# vpac_targetdb register map
Vendor: Texas Instruments
Peripheral module from a debugger description file (folder hts_vpac).
Registers are 32-bit, read-write, no defined reset value unless marked. A register's access mark holds for its fields unless they carry their own. Offsets are as the file gives them; lines under a group give offsets from that group; [hi:lo] are bit positions; {n}, {i} and the like mark numbered series; 'fields as' and 'values as' point back to an identical list; <NAME> marks a mode.

## VPAC (part 1 of 8) — Vision Pre-Processing Accelerator (VPAC)
0x0C SYSCONFIG — system Configuration
  [1] CLKCG_OVERIDE — Override power saving clock gating inserted by design. '1' -> Allow the clock to be free running (except for gated pixel clock) '0' -> Clock can be gated as planned by the design
0x0C GLBCE_CONTROL1 access per field — Connected to iridix_control1 parameter in GLBCE Core
  [7:0] CONTROL1 rw — Connected Control1 port
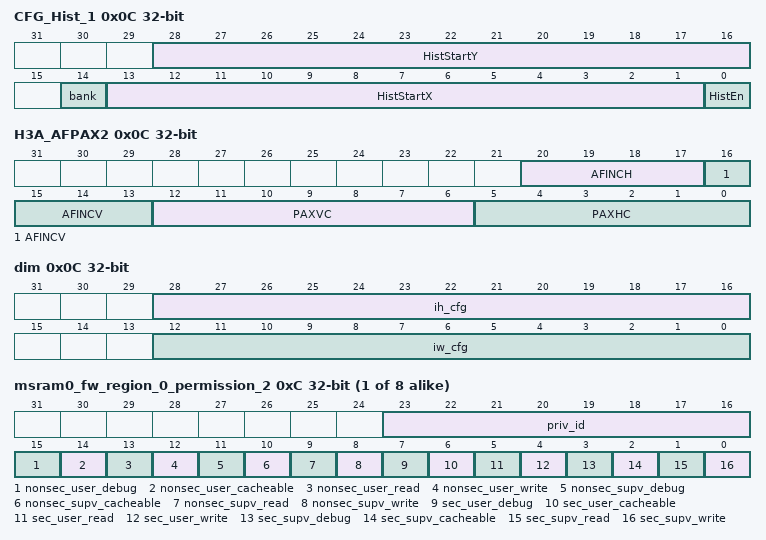
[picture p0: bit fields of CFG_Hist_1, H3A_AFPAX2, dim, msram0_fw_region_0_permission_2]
0x0C CFG_Hist_1 access per field — Configuration-1 Register for histogram
  [28:16] HistStartY rw — Y Start for Histogram ROI, should be >= 1
  [14] bank rw — bank select for Histogram
  [13:1] HistStartX rw — X Start for Histogram ROI, should be even
  [0] HistEn rw — Enable bit for histogram
0x0C PWL1_EN access per field — Long frame PWL enable
  [0] ENABLE rw
0x0C H3A_AFPAX2 access per field — Setup for the AF Engine Paxel Configuration
  [20:17] AFINCH rw — AF Engine Column Increments Number of columns to increment in a paxel plus 1 multiplied by 2 Thus, the number of columns that can be skipped between two processed line pairs is 2-32 [even] The starting two columns in a paxel are first processed before this field is applied This must be set so that there are at least 4 samples on a line when combined with the number of horizontal paxels * This value is shadowed and latched on the rising edge of VSYNC
  [16:13] AFINCV rw — AF Engine Line Increments Number of lines to increment in a Paxel plus 1 multiplied by 2 Incrementing the line in a paxel is always done on a line pair due to the fact that the RGB pattern falls in two lines If all the lines are to be processed, this field should be set to zero, and thus line count is incremented by 2 following a line pair Thus, the number of lines that can be skipped between two processed line pairs is 0-30 [even] The starting two lines in a paxel are first processed before this field is applied * This value is shadowed and latched on the rising edge of VSYNC
  [12:6] PAXVC rw — AF Engine Vertical Paxel Count The number of paxels in the vertical direction plus 1 The maximum number of vertical paxels in a frame should not exceed 128 The value should be set to ensure that the bandwidth requirements and buffer size are not exceeded * This value is shadowed and latched on the rising edge of VSYNC
  [5:0] PAXHC rw — AF Engine Horizontal Paxel Count The number of paxels in the horizontal direction plus 1 It is illegal to set a number that is greater than 35 [total of 36 paxels in the horizontal direction] The minimum number of paxels should be 2 [valid range for the field is 1-35] * This value is shadowed and latched on the rising edge of VSYNC
0x0C dim — Input Output Frame dimensions in units of pixels. Same value for input and output
  [28:16] ih_cfg — (U13) input height in units of pixels minus 1.
  [12:0] iw_cfg — (U13) input width in units of pixels minus 1. Max usable value determined by populated line buffer RAM size
0x0C YEE_SHIFT — The YEE Shift register controls
  [5:0] yee_shift
{0xC+0x20*i} msram0_fw_region_{i}_permission_2 (i=0..7) — The FW Region {i} Permission 2 Register defines the permissions for the slave ksbus_msram0.slv region {i} firewall.
  [23:16] priv_id — Allowed privid.
  [15] nonsec_user_debug — Non-secure user debug allowed.
  [14] nonsec_user_cacheable — Non-secure user cacheable allowed.
  [13] nonsec_user_read — Non-secure user read allowed.
  [12] nonsec_user_write — Non-secure user write allowed.
  [11] nonsec_supv_debug — Non-secure supervisor debug allowed.
  [10] nonsec_supv_cacheable — Non-secure supervisor cacheable allowed.
  [9] nonsec_supv_read — Non-secure supervisor read allowed.
  [8] nonsec_supv_write — Non-secure supervisor write allowed.
  [7] sec_user_debug — Secure user debug allowed.
  [6] sec_user_cacheable — Secure user cacheable allowed.
  [5] sec_user_read — Secure user read allowed.
  [4] sec_user_write — Secure user write allowed.
  [3] sec_supv_debug — Secure supervisor debug allowed.
  [2] sec_supv_cacheable — Secure supervisor cacheable allowed.
  [1] sec_supv_read — Secure supervisor read allowed.
  [0] sec_supv_write — Secure supervisor write allowed.
0x10 eoi_reg — End of Interrupt Register
  [7:0] eoi_vector — End of Interrupt Vector
0x10 reserved_svbus — Reference other documents that contain the ECC RAM wrapper and EDC controller serial vbus register sets.
  [31:0] data — Serial VBUS register data
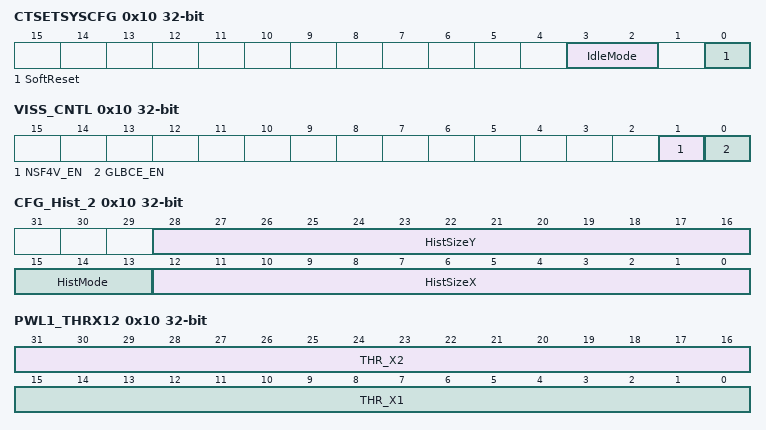
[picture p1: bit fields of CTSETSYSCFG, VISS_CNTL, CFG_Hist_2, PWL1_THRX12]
0x10 CTSETSYSCFG access per field — CTSET system configuration register
  [3:2] IdleMode rw — Sets the Idle Mode for CTSET (0=Force Idle, 1=No Idle, 2=Smart Idle, 3= Smart Idle wakeup)
  [0] SoftReset rw — This will reset entire CTSET, except the registers and the CFG interface. This bit is automatically cleared by hardware. Reads always return 0
0x10 reserved_svbus — Reference other documents that contain the ECC RAM wrapper and EDC controller serial vbus register sets.
  [31:0] data — Serial VBUS register data
0x10 MESHTABLE_CFG — Defines the down-sampling factors used for the mesh offset tables
  [2:0] M — Mesh table down-sampling factor (by 2^M in both horizontal and Vertical). 0: 1 - no down-sampling 1: 2 - 2x down-sampling 2: 4 3: 8 4: 16 5: 32 6: 64 7:128
0x10 reserved_svbus — Reference other documents that contain the ECC RAM wrapper and EDC controller serial vbus register sets.
  [31:0] data — Serial VBUS register data
0x10 VISS_CNTL — VISS top control
  [1] NSF4V_EN — '1' -> NSF4V is ON , '0' -> NSF4V is off i.e. bypass NSF4V. Read the bit status for completion of write. When '0', Configuration access to NSF4V will result in Error response.
  [0] GLBCE_EN — '1' -> GLBCE is ON , '0' -> GLBCE is off i.e. bypass GLBCE. Read the bit status for completion of write. When '0', Configuration access to GLBCE End points (MMR, Statastics memory ) will result in Error response.
0x10 GLBCE_BLACK_LEVEL access per field — Black Level Register (black_level)
  [15:0] VAL rw — The value stored in Black Level Port will be used as zero level for GLBCE processing in all unsigned data channels Data below Black level will not be processed and stay unchanged
0x10 CFG_Hist_2 access per field — Configuration-2 Register for histogram
  [28:16] HistSizeY rw — Y Size (Height) for Histogram ROI
  [15:13] HistMode rw — Histogram Mode(0:Col-0(R),1:Col-1(G),2:Col-2(B),3:MuxC1_4,4:R+2G+B/4 )
  [12:0] HistSizeX rw — X Size (Width) for Histogram ROI, should be > 256 and even
0x10 PWL1_THRX12 — Long frame PWL threshold X1 and X2 - Unsigned
  [31:16] THR_X2 — threshold X2
  [15:0] THR_X1 — threshold X1
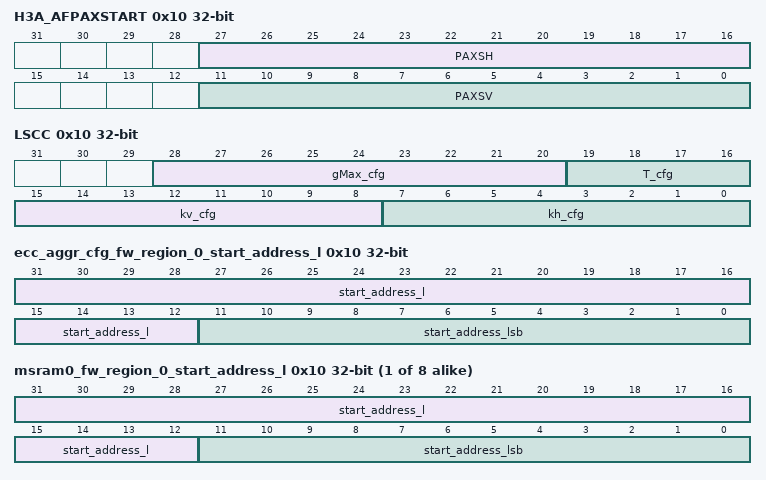
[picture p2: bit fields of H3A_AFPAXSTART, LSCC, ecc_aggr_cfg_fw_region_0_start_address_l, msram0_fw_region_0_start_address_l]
0x10 H3A_AFPAXSTART access per field — Start Position for AF Engine Paxels
  [27:16] PAXSH rw — AF Engine Paxel Horizontal start position Range: 2-4094 PAXSH must be equal to or greater than [IIRSH + 2] This value must be even if Vertical mode is not enabled If Vertical mode is enabled then the lower bit of PAXSH and IIRSH must be equal * This value is shadowed and latched on the rising edge of VSYNC
  [11:0] PAXSV rw — AF Engine Paxel Vertical start position Range: 0-4095 Sets the vertical line for the first paxel This value must be greater then or equal to 8 if the vertical mode is enabled * This value is shadowed and latched on the rising edge of VSYNC
0x10 LSCC — Lens Shading Correction Compensation. First control register
  [28:20] gMax_cfg — (U4.5) LSCC maximum gain. Any calculated value is clipped to this max value
  [19:16] T_cfg — (U4) LSCC radius dynamic range select. T is the right shift amount prior to MSB clip.
  [15:8] kv_cfg — (U2.6) LSCC horizontal or Y Gain for elliptical lens
  [7:0] kh_cfg — (U2.6) LSCC vertical or X Gain for elliptical lens
{0x10+0x10*i} YEE_COEF_R{i}_C0 (i=0..2) — The YEE Coefficient Row x Column x defines the
  [9:0] yee_coef_r{i}_c0 — The
0x10 ecc_aggr_cfg_fw_region_0_start_address_l access per field — The FW Region 0 Start Address Low Register defines the start address bits 31 to 0 for the slave ksdw_ecc_aggr.cfg region 0 firewall.
  [31:12] start_address_l rw — Start address bits 31 to 12. Lowest 12 bits are forced to 0 as address must be 4KB aligned.
  [11:0] start_address_lsb ro — Start address bits 11 to 0 are forced to 0 as address must be 4KB aligned.
{0x10+0x20*i} msram0_fw_region_{i}_start_address_l access per field (i=0..7) — The FW Region {i} Start Address Low Register defines the start address bits 31 to 0 for the slave ksbus_msram0.slv region {i} firewall.
  fields as ecc_aggr_cfg_fw_region_0_start_address_l
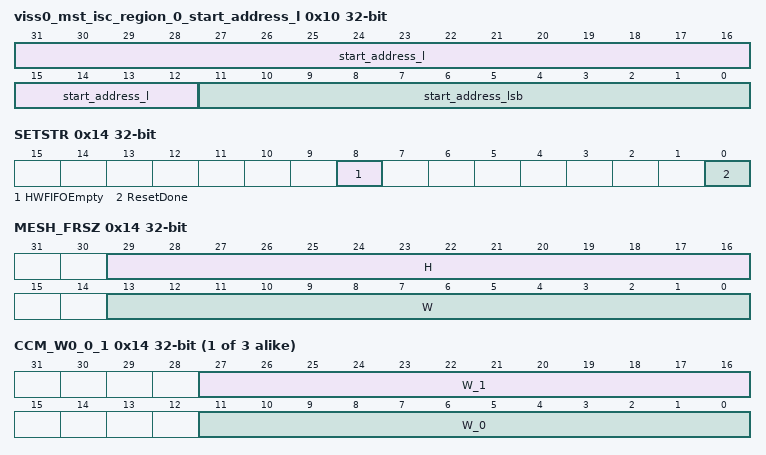
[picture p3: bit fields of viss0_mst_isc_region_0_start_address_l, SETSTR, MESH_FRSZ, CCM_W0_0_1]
0x10 viss0_mst_isc_region_0_start_address_l — The ISC Region 0 Start Address Low Register defines the start address bits 31 to 0 for the master .viss0_mst region 0 ISC.
  [31:12] start_address_l — Start address bits 31 to 12.
  [11:0] start_address_lsb — Start address bits 11 to 0 must be 0 as address must be 4KB aligned in address mode. Can also be channel number in channel mode.
0x14 intr_vector_reg ro — Interrupt Vector Register
  [31:0] intr_vector
0x14 SETSTR ro — CTSET status register
  [8] HWFIFOEmpty — System Event Trace FIFO status, 1 is empty, 0 means captured data not yet exported
  [0] ResetDone — Reset status, 0 means reset ongoing, 1 indicates completed
0x14 MESH_FRSZ — Mesh data mapping is available for this Frame size. Actual number of mesh data entires depend Mesh Frame size and Mesh sampling factor. This Frame size is independent from COMPUTE_FRSZ
  [29:16] H — Mesh Frame height in Lines
  [13:0] W — Mesh Frame Width
0x14 GLBCE_WHITE_LEVEL access per field — White Level Register (white_level)
  [15:0] VAL rw — The value stored in White Level Port will be used as white level for GLBCE processing in all unsigned data channels Data above White level will not be processed and stay unchanged
{0x14+0xC*i} CCM_W{i}_0_1 access per field (i=0..2) — CCM Weights for Row{i}
  [27:16] W_1 rw — Weight W_{10i+1:02} : (S12 b)
  [11:0] W_0 rw — Weight W_{10i:02} : (S12 b)
0x14 PWL1_THRX3 access per field — Long frame PWL threshold X3 - Unsigned
  [15:0] THR_X3 rw — threshold X3
0x14 H3A_AFIIRSH access per field — Start Position for IIRSH
  [11:0] IIRSH rw — AF Engine IIR Horizontal Start Position Range from 0-4094 When the horizontal position of a line equals this value the shift registers are cleared on the next pixel This value must be even if Vertical mode is not enabled If vertical mode is enabled then the lower bit must match the paxel horizontal start position * This value is shadowed and latched on the rising edge of VSYNC
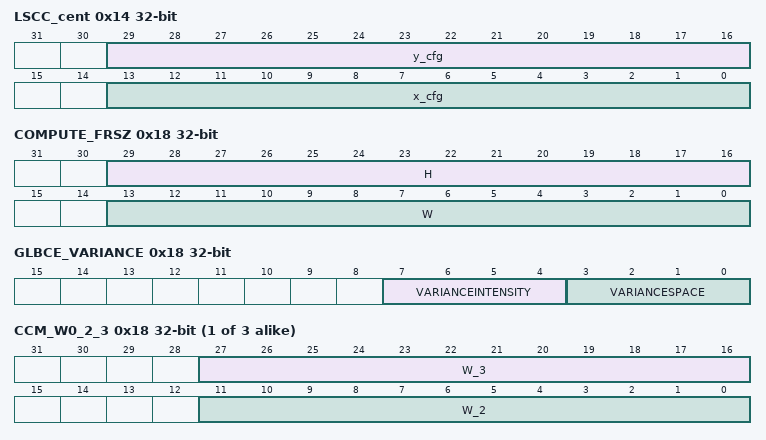
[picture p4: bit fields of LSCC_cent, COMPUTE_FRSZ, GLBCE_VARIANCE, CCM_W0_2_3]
0x14 LSCC_cent — Lens Shading Correction Compensation. Programmable Center of frame
  [29:16] y_cfg — (S14) Vertical (Y) position of lens center
  [13:0] x_cfg — (S14) Horizontal (X) position of lens center
{0x14+0x10*i} YEE_COEF_R{i}_C1 (i=0..2) — The YEE Coefficient Row x Column x defines the
  [9:0] yee_coef_r{i}_c1 — The
0x14 ecc_aggr_cfg_fw_region_0_start_address_h — The FW Region 0 Start Address High Register defines the start address bits 47 to 32 for the slave ksdw_ecc_aggr.cfg region 0 firewall.
  [15:0] start_address_h — Start address bits 47 to 32.
{0x14+0x20*i} msram0_fw_region_{i}_start_address_h (i=0..7) — The FW Region {i} Start Address High Register defines the start address bits 47 to 32 for the slave ksbus_msram0.slv region {i} firewall.
  [15:0] start_address_h — Start address bits 47 to 32.
0x14 viss0_mst_isc_region_0_start_address_h — The ISC Region 0 Start Address High Register defines the start address bits 47 to 32 for the master .viss0_mst region 0 ISC.
  [15:0] start_address_h — Start address bits 47 to 32.
0x18 DBGTIMELOW ro — The 32 low order bits of the debug time value supplied on the time input interface
  [31:0] DBGTIME — debug time
0x18 COMPUTE_FRSZ — H corresponds to the total number of lines to process. W corresponds to the number of pixels to process in each line. This parameters must be loaded as actual pixel counts, NOT pixel counts - 1. W and H must both be less than or equal to 8192. The hardware does not support output coordinates larger than 8192. Therefore, COMPUTE_FRSZ.W + INITXY.INITX must be no larger than 8192. Also COMPUTE_FRSZ.H + INITXY.INITY must be no larger than 8192.
  [29:16] H — Output Frame height in Lines. Must be even
  [13:0] W — Output Frame Width. Must be even
0x18 GLBCE_VARIANCE access per field — Affects the sensitivity of the transform to different areas of the image, and can be increased in order to emphasize small regions (e.g. faces). If this parameter is set to zero, the sensitivity to the small areas is maximal. The transform becomes more local. When the parameter is set to 0xFF the transform deemphasizes small local details, and transform becomes more global e.g. the sky at the top of the frame can affect flowers at the bottom of the frame.
  [7:4] VARIANCEINTENSITY rw — Variance Intensity - Sets the degree of sensitivity in the luminance domain Maximum Variance is 0xF, and minimum Variance is 0x0
  [3:0] VARIANCESPACE rw — Variance Space - Sets the degree of spatial sensitivity of the algorithm As this parameter is made smaller, the algorithm focuses on smaller regions within the image Maximum Variance is 0xF, and minimum Variance is 0x0
{0x18+0xC*i} CCM_W{i}_2_3 access per field (i=0..2) — CCM Weights for Row{i}
  [27:16] W_3 rw — Weight W_{10i+3:02} : (S12 b)
  [11:0] W_2 rw — Weight W_{10i+2:02} : (S12 b)
{0x14+4i} PWL1_THRY{i} access per field (i=1..3) — Long frame PWL threshold Y{i} - Unsigned
  [23:0] THR_Y{i} rw — threshold Y{i}
0x18 H3A_AFBUFST access per field — SDRAM destination address for AF engine statistics
  [31:5] AFBUFST rw — SDRAM destination address for AF engine statistics The SDRAM destination address for the AF statistics The 6 LSBs are ignored, address shall be on a 64-byte boundary This field can be altered even when the AF is busy Change will take place only for the next frame However, note that reading this register will always give the latest value
{0x18+0x10*i} YEE_COEF_R{i}_C2 (i=0..2) — The YEE Coefficient Row x Column x defines the
  [9:0] yee_coef_r{i}_c2 — The
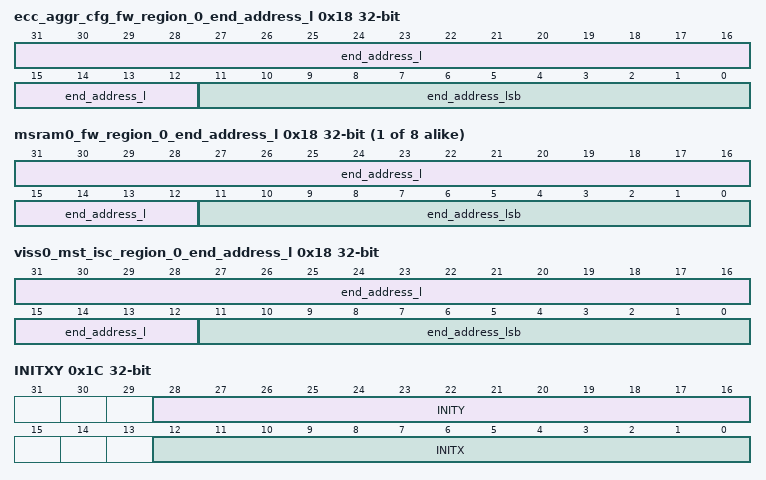
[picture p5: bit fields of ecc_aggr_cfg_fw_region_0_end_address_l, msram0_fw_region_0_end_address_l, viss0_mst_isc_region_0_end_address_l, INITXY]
0x18 ecc_aggr_cfg_fw_region_0_end_address_l access per field — The FW Region 0 End Address Low Register defines the end address bits 31 to 0 to include for the slave ksdw_ecc_aggr.cfg region 0 firewall.
  [31:12] end_address_l rw — End address bits 31 to 12 to include in the match. Lowest 12 bits are forced to 1s as address must be 4KB aligned.
  [11:0] end_address_lsb ro — End address bits 11 to 0 are forced to 1s as address must be 4KB aligned minus 1.
{0x18+0x20*i} msram0_fw_region_{i}_end_address_l access per field (i=0..7) — The FW Region {i} End Address Low Register defines the end address bits 31 to 0 to include for the slave ksbus_msram0.slv region {i} firewall.
  fields as ecc_aggr_cfg_fw_region_0_end_address_l
0x18 viss0_mst_isc_region_0_end_address_l access per field — The ISC Region 0 End Address Low Register defines the end included address bits 31 to 0 for the master .viss0_mst region 0 ISC.
  [31:12] end_address_l rw — End address bits 31 to 12 to include in the match.
  [11:0] end_address_lsb ro — End address bits 11 to 0 are forced to Fs as address must be 4KB aligned.
0x1C DBGTIMEHI ro — The 32 high order bits of the debug time value supplied on the time input interface
  [31:0] DBGTIME — debug time
0x1C INITXY — LDC Initial Output Co-ordinate to process
  [28:16] INITY — Output starting Y-coordinate. must be even
  [12:0] INITX — Output starting X-coordinate. must be even
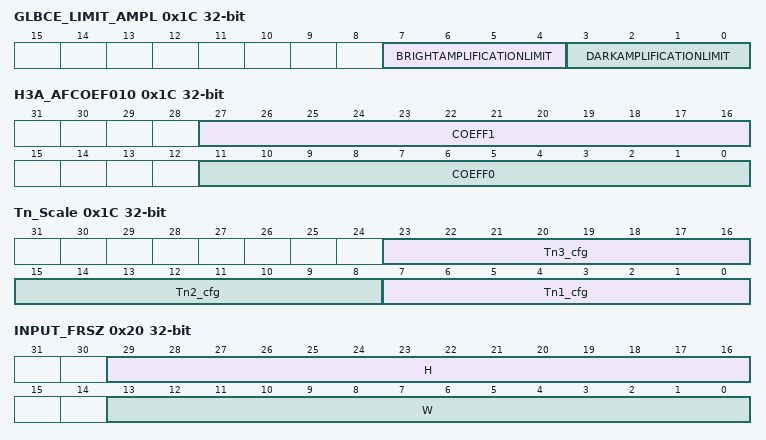
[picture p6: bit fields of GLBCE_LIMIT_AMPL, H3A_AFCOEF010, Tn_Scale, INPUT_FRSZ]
0x1C GLBCE_LIMIT_AMPL access per field — The parameters dark amplification limit bright amplification limit are used to restrict the luminance space in which GLBCE can adaptively generate tone curves for each pixel.
  [7:4] BRIGHTAMPLIFICATIONLIMIT rw — Bright amplification limit - The resultant tone curve cannot be lower than bright amplification limit line controlled by the bright amplification limit parameter See Chapter 4 of the spec document for more explanation Maximum limit is 0xF, when the value is 0x0 there is no limit
  [3:0] DARKAMPLIFICATIONLIMIT rw — Dark amplification limit - The resultant tone curve cannot be higher than dark amplification limit line controlled by the dark amplification limit parameter See Chapter 4 of the spec for more explanation Maximum limit is 0xF, when the value is 0x0 there is no limit
{0x1C+0xC*i} CCM_OFFSET_{i} access per field (i=0..2) — CCM OFFSET for Row{i}
  [12:0] OFFSET_{i} rw — OFFSET_{i} : (S13 b)
0x1C H3A_AFCOEF010 access per field — IIR filter coefficient data for SET 0.
  [27:16] COEFF1 rw — AF Engine IIR filter Coefficient #1 [Set 0] The range is signed -32 LTEQ value LTEQ 31 +63/64
  [11:0] COEFF0 rw — AF Engine IIR filter Coefficient #0 [Set 0] The range is signed -32 LTEQ value LTEQ 31 +63/64
0x1C Tn_Scale — Tn scaling factor multiplied by all 4 color components Tn after 12 segment PWL. Different scaling factor per level
  [23:16] Tn3_cfg — (U3.5) Level3. Sub-bands 7, 8, 9
  [15:8] Tn2_cfg — (U3.5) Level2. Sub-bands 4, 5, 6
  [7:0] Tn1_cfg — (U3.5) Level1. Sub-bands 0, 1, 2
0x1C ecc_aggr_cfg_fw_region_0_end_address_h — The FW Region 0 End Address High Register defines the end address bits 47 to 32 to include for the slave ksdw_ecc_aggr.cfg region 0 firewall.
  [15:0] end_address_h — End address bits 47 to 32 to include in the match.
{0x1C+0x20*i} msram0_fw_region_{i}_end_address_h (i=0..7) — The FW Region {i} End Address High Register defines the end address bits 47 to 32 to include for the slave ksbus_msram0.slv region {i} firewall.
  fields as ecc_aggr_cfg_fw_region_0_end_address_h
0x1C viss0_mst_isc_region_0_end_address_h — The ISC Region 0 End Address High Register defines the end address bits 47 to 32 for the master .viss0_mst region 0 ISC.
  [15:0] end_address_h — End address bits 47 to 32.
0x20 INPUT_FRSZ — Defines the total input frame size
  [29:16] H — Input Frame height in Lines. Must be even
  [13:0] W — Input Frame Width in Pixels. Must be even
0x20 GLBCE_DITHER access per field — Dithering Register (dither)
  [2:0] DITHER rw — 000b: No dithering 001b: One least significant bit of the output signal is dithered 010b: Two bits are dithered 011b: Three bits are dithered 100b: Four bits are dithered All other values : Four bits are dithered
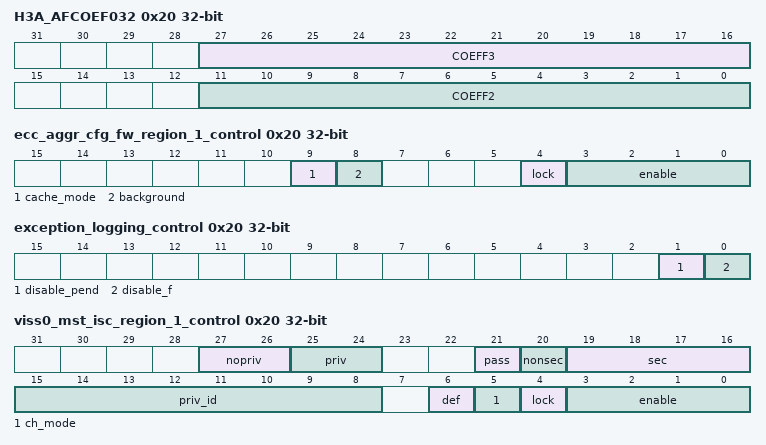
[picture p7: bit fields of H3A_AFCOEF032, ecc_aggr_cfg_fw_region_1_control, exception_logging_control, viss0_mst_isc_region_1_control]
0x20 H3A_AFCOEF032 access per field — IIR filter coefficient data for SET 0.
  [27:16] COEFF3 rw — AF Engine IIR filter Coefficient #3 [Set 0] The range is signed -32 LTEQ value LTEQ 31 +63/64
  [11:0] COEFF2 rw — AF Engine IIR filter Coefficient #2 [Set 0] The range is signed -32 LTEQ value LTEQ 31 +63/64
0x20 U_knee — U suppression curve knee. Same knee value for all 9 levels x 4 color components.
  [5:0] U_knee_cfg — (U0.6) U Suppress curve knee. X (LL2) value which separates constant suppression of 1.0 from linear suppression.
0x20 exception_logging_control — The Exception Logging Control Register controls the exception logging.
  [1] disable_pend — Disables logging pending when set.
  [0] disable_f — Disables logging when set.
0x20 ecc_aggr_cfg_fw_region_1_control — The FW Region 1 Control Register defines the control fields for the slave ksdw_ecc_aggr.cfg region 1 firewall.
  [9] cache_mode — Cache mode for region. Set to 1 to check cache permissions. Set to 0 to ignore cache permissions.
  [8] background — Background enable for region. There can be 1 backgroun region per FW and foreground regions can have overlapping addresses only with the background region.
  [4] lock — Lock region. Once set region values cannot be modified.
  [3:0] enable — Enable region. A value of 0xA enables, others disable.
0x20 exception_logging_control — The Exception Logging Control Register controls the exception logging.
  fields as exception_logging_control
0x20 viss0_mst_isc_region_1_control access per field — The ISC Region 1 Control Register defines the control fields for the master .viss0_mst region 1 ISC.
  [27:26] nopriv rw — Clear output priv attribute. If each bit is set then the outgoing priv bit is cleared.
  [25:24] priv rw — Set outgoing priv attribute. If each bit is set then the outgoing priv bit is set.
  [21] pass rw — No privID replacement, pass through value.
  [20] nonsec rw — Make outgoing non-secure.
  [19:16] sec rw — Make outgoing secure. A value of 0xA enables, others disable.
  [15:8] priv_id rw
  [6] def ro — Default region indication. The default region is used when all other regions do not match.
  [5] ch_mode rw — Enable channel mode to match region to a chanid value. Otherwise use address mode to match region to an address range.
  [4] lock rw — Lock region. Once set the region values cannot be modified.
  [3:0] enable rw — Enable region. A value of 0xA enables, others disable.
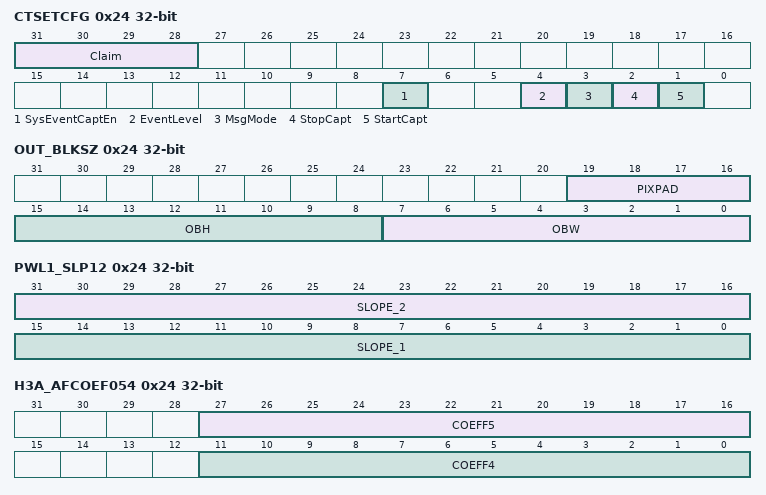
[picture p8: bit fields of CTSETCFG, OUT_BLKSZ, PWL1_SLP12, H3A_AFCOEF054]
0x24 CTSETCFG access per field — The 32 low order bits of the debug time value supplied on the time input interface The 32 high order bits of the debug time value supplied on the time input interface. Reading DBGTIMEHI latches the lower 32 bits of debug time value CTSET configuration register
  [31:28] Claim rw — Claim control and status. To program any bits other than 31 : 28, CTSET ownership must be claimed using bits 31 : 28.
  [7] SysEventCaptEn rw — When 1 the System event capture is enabled
  [4] EventLevel rw — 0 enables low level event detection, 1 enables high level event detection
  [3] MsgMode rw — Message generated based on event detection, 0 is sampling window, 1 is event detection
  [2] StopCapt rw — Stop capturing system events from external trigger detection
  [1] StartCapt rw — Start capturing system events from external trigger detection
0x24 OUT_BLKSZ — LDC Output Block parameter registers. These parameters represent actual pixel counts, NOT pixel counts - 1. OBW must be greater than 0 and less than or equal to frame width (COMPUTE_FRSZ.W). OBH must be greater than 0 and less than or equal to frame height (COMPUTE_FRSZ.H).
  [19:16] PIXPAD — Pixel pad
  [15:8] OBH — Output block height must be >0 and even
  [7:0] OBW — Output block width, must be >0 and multiple of 8
0x24 GLBCE_SLOPE_MAX access per field — Slope Max Limit Register (slope_max)
  [7:0] SLOPEMAXLIMIT rw — Slope Max Limit - Slope Max Limit is used to restrict the slope of the tone-curve generated by GLBCE When Slope Max Limit parameter is set to 0xFF, the tone curve slope, generated by GLBCE is not limited [maximum slope 15] When this value is set to 00 GLBCE will not generate the tone-curve with slope greater than 16/15 [48] Intermediate values of Slope Limit are linear interpolation between minimum and maximum values Recommended Slope Max Limit range is 20h-60h For noisy images less value should be used See Chapter 4 of GLBCE datasheet for more explanation
0x24 PWL1_SLP12 — Long frame PWL slope 1 and 2 - Unsigned
  [31:16] SLOPE_2, [15:0] SLOPE_1
0x24 H3A_AFCOEF054 access per field — IIR filter coefficient data for SET 0.
  [27:16] COEFF5 rw — AF Engine IIR filter Coefficient #5 [Set 0] The range is signed -32 LTEQ value LTEQ 31 +63/64
  [11:0] COEFF4 rw — AF Engine IIR filter Coefficient #4 [Set 0] The range is signed -32 LTEQ value LTEQ 31 +63/64
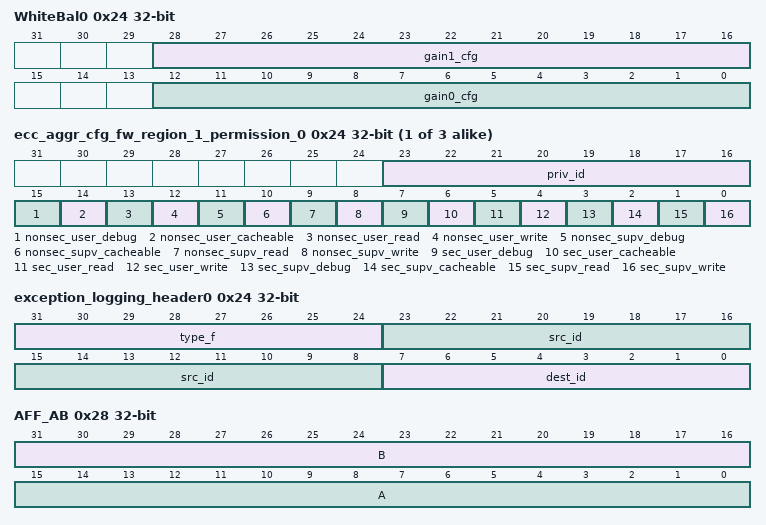
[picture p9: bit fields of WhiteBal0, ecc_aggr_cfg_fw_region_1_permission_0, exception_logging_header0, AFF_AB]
0x24 WhiteBal0 — White Balance Gain (Part0). Separate Gain for each of 4 colors
  [28:16] gain1_cfg — (U4.9) Gain for color 1
  [12:0] gain0_cfg — (U4.9) Gain for color 0
0x24 exception_logging_header0 ro — The Exception Logging Header 0 Register contains the first word of the header.
  [31:24] type_f — Type.
  [23:8] src_id — Source ID.
  [7:0] dest_id — Destination ID.
{0x24+4i} ecc_aggr_cfg_fw_region_1_permission_{i} (i=0..2) — The FW Region 1 Permission {i} Register defines the permissions for the slave ksdw_ecc_aggr.cfg region 1 firewall.
  fields as msram0_fw_region_0_permission_2
0x24 exception_logging_header0 ro — The Exception Logging Header 0 Register contains the first word of the header.
  fields as exception_logging_header0
0x28 SETSPLREG access per field — System Event Sampling Window register
  [7:0] WindowSize rw — System events sampling window size expressed as CTSET cycles
0x28 AFF_AB — LDC Affine Transwarp A/B
  [31:16] B — Affine transwarp B (S16Q12)
  [15:0] A — Affine transwarp A (S16Q12)
0x28 GLBCE_SLOPE_MIN access per field — Slope Min Limit Register (slope_min)
  [7:0] SLOPEMINLIMIT rw — Slope Min Limit - Slope Min Limit is used to restrict the slope of the tone-curve generated by GLBCE When Slope Min Limit parameter is set to 0x00, the tone curve slope, generated by GLBCE is not limited When this value is set to FF GLBCE will not generate the tone-curve with slope less than 3/4 Intermediate values of Slope Limit are linear interpolation between minimum and maximum values Recommended Slope Min Limit range is 00h-C0h See Chapter 4 in GLBCE datasheet for more explanation
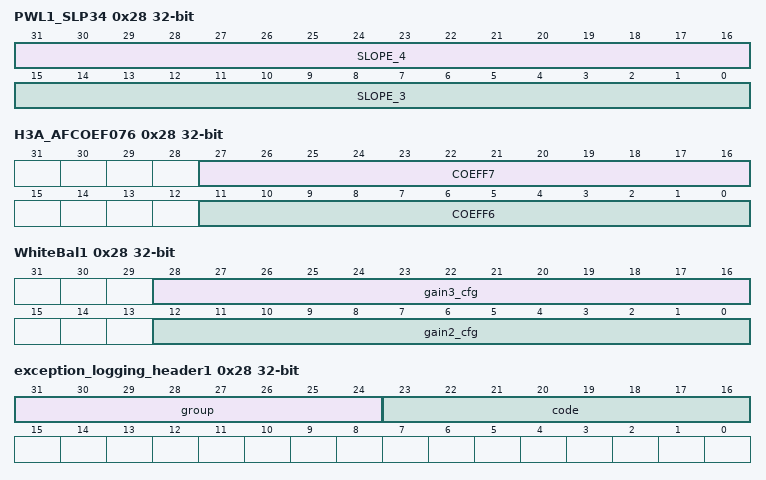
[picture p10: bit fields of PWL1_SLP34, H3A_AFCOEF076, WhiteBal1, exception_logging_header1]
0x28 PWL1_SLP34 — Long frame PWL slope 3 and 4 - Unsigned
  [31:16] SLOPE_4, [15:0] SLOPE_3
0x28 H3A_AFCOEF076 access per field — IIR filter coefficient data for SET 0.
  [27:16] COEFF7 rw — AF Engine IIR filter Coefficient #7 [Set 0] The range is signed -32 LTEQ value LTEQ 31 +63/64
  [11:0] COEFF6 rw — AF Engine IIR filter Coefficient #6 [Set 0] The range is signed -32 LTEQ value LTEQ 31 +63/64
0x28 WhiteBal1 — White Balance Gain (Part1). Separate Gain for each of 4 colors
  [28:16] gain3_cfg — (U4.9) Gain for color 3
  [12:0] gain2_cfg — (U4.9) Gain for color 2
0x28 exception_logging_header1 ro — The Exception Logging Header 1 Register contains the second word of the header.
  [31:24] group, [23:16] code
0x28 exception_logging_header1 ro — The Exception Logging Header 1 Register contains the second word of the header.
  [31:24] group, [23:16] code
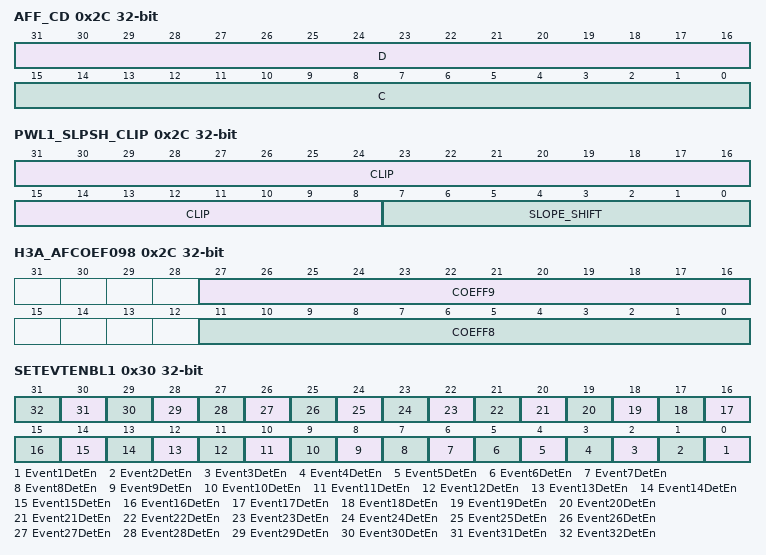
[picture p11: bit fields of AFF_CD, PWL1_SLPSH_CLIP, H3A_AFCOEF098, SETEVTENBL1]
0x2C AFF_CD — LDC Affine Transwarp C/D
  [31:16] D — Affine transwarp D (S16Q12)
  [15:0] C — Affine transwarp C (S16Q3)
{0x2C+4i} GLBCE_LUT_FI_{i:02} access per field (i=0..32) — Asymmetry Function LUT The Asymmetry Function Lookup Table port geometry is 33 words, each of which is 16 bits. The Asymmetry function is used to balance the GLBCE effect between the dark and bright regions of the image.
  [15:0] VAL rw — Asymmetry LUT Entry
0x2C PWL1_SLPSH_CLIP — Long frame PWL slope shift and clip
  [31:8] CLIP — clip value
  [7:0] SLOPE_SHIFT — shift value for slope, must not exceed decimal 33.
0x2C H3A_AFCOEF098 access per field — IIR filter coefficient data for SET 0.
  [27:16] COEFF9 rw — AF Engine IIR filter Coefficient #9 [Set 0] The range is signed -32 LTEQ value LTEQ 31 +63/64
  [11:0] COEFF8 rw — AF Engine IIR filter Coefficient #8 [Set 0] The range is signed -32 LTEQ value LTEQ 31 +63/64
0x2C exception_logging_data0 ro — The Exception Logging Data 0 Register contains the first word of the data.
  [31:0] addr_l — Address lower 32 bits.
0x2C exception_logging_data0 ro — The Exception Logging Data 0 Register contains the first word of the data.
  [31:0] addr_l — Address lower 32 bits.
0x30 SETEVTENBL1 — System event detection enable register 1
  [n-1] Event{n}DetEn (n=1..32) — Event({n}) Detection Enable
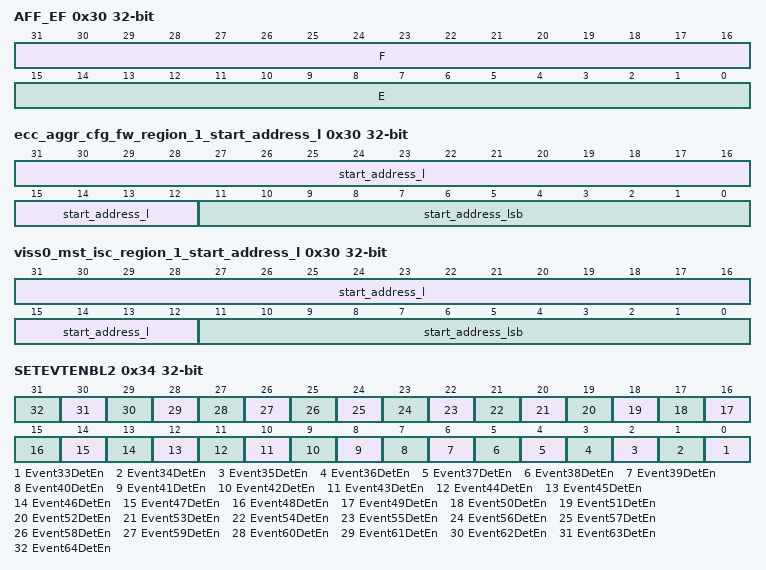
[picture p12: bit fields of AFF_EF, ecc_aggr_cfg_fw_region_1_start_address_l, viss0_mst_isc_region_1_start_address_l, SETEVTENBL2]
0x30 AFF_EF — LDC Affine Transwarp E/F
  [31:16] F — Affine transwarp F (S16Q3)
  [15:0] E — Affine transwarp E (S16Q12)
0x30 PWL1_OFF1 access per field — Long frame Offset 1
  [23:0] OFST00 rw — S24, Offset at pixel 00
0x30 H3A_AFCOEF0010 access per field — IIR filter coefficient data for SET 0.
  [11:0] COEFF10 rw — AF Engine IIR filter Coefficient #10 [Set 0] The range is signed -32 LTEQ value LTEQ 31 +63/64
0x30 exception_logging_data1 ro — The Exception Logging Data 1 Register contains the second word of the data.
  [15:0] addr_h — Address upper 16 bits.
0x30 ecc_aggr_cfg_fw_region_1_start_address_l access per field — The FW Region 1 Start Address Low Register defines the start address bits 31 to 0 for the slave ksdw_ecc_aggr.cfg region 1 firewall.
  fields as ecc_aggr_cfg_fw_region_0_start_address_l
0x30 exception_logging_data1 ro — The Exception Logging Data 1 Register contains the second word of the data.
  [15:0] addr_h — Address upper 16 bits.
0x30 viss0_mst_isc_region_1_start_address_l — The ISC Region 1 Start Address Low Register defines the start address bits 31 to 0 for the master .viss0_mst region 1 ISC.
  fields as viss0_mst_isc_region_0_start_address_l
0x34 SETEVTENBL2 — System event detection enable register 2 (if number of events > 32)
  [n-33] Event{n}DetEn (n=33..64) — Event({n}) Detection Enable
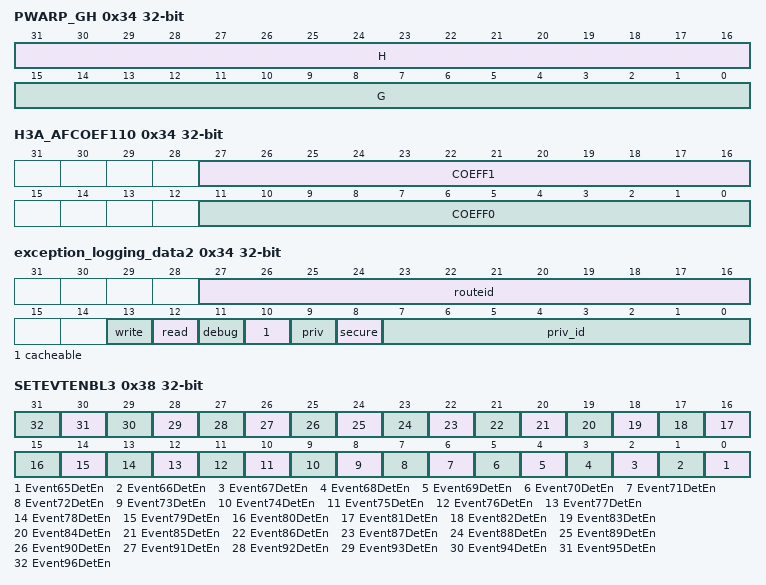
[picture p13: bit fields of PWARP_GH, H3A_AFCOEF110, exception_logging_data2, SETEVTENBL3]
0x34 PWARP_GH — LDC Perspective Transformation Parameters, G and H
  [31:16] H — Perspective Transformation H (S16Q23)
  [15:0] G — Perspective Transformation H (S16Q23)
0x34 PWL1_OFF2 access per field — Long frame Offset 2
  [23:0] OFST01 rw — S24, Offset at pixel 01
0x34 H3A_AFCOEF110 access per field — IIR filter coefficient data for SET 1.
  [27:16] COEFF1 rw — AF Engine IIR filter Coefficient #1 [Set 1] The range is signed -32 LTEQ value LTEQ 31 +63/64
  [11:0] COEFF0 rw — AF Engine IIR filter Coefficient #0 [Set 1] The range is signed -32 LTEQ value LTEQ 31 +63/64
0x34 exception_logging_data2 ro — The Exception Logging Data 2 Register contains the third word of the data.
  [27:16] routeid, [13] write, [12] read, [11] debug, [10] cacheable, [9] priv, [8] secure, [7:0] priv_id
0x34 ecc_aggr_cfg_fw_region_1_start_address_h — The FW Region 1 Start Address High Register defines the start address bits 47 to 32 for the slave ksdw_ecc_aggr.cfg region 1 firewall.
  [15:0] start_address_h — Start address bits 47 to 32.
0x34 exception_logging_data2 ro — The Exception Logging Data 2 Register contains the third word of the data.
  fields as exception_logging_data2
0x34 viss0_mst_isc_region_1_start_address_h — The ISC Region 1 Start Address High Register defines the start address bits 47 to 32 for the master .viss0_mst region 1 ISC.
  [15:0] start_address_h — Start address bits 47 to 32.
0x38 SETEVTENBL3 — System event detection enable register 3 (if number of events > 64)
  [n-65] Event{n}DetEn (n=65..96) — Event({n}) Detection Enable
0x38 MESH_BASE_H — Higher 16-bit of Mesh Table Base Address
  [15:0] ADDR — Higher 16-bit of Read Base address for mesh offset table
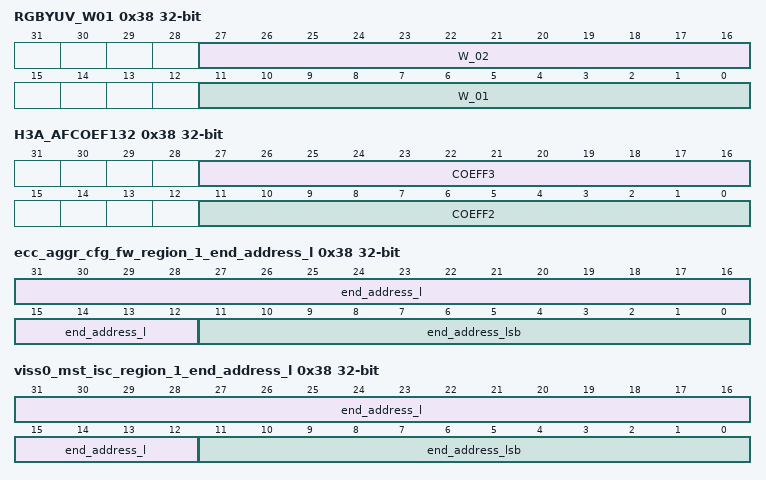
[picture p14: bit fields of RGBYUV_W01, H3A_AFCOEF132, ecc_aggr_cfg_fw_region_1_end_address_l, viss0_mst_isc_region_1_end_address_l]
0x38 RGBYUV_W01 access per field — Weight/Offset for Row0
  [27:16] W_02 rw — Weight W_02 : (S12 b)
  [11:0] W_01 rw — Weight W_01 : (S12 b)
0x38 PWL1_OFF3 access per field — Long frame Offset 3
  [23:0] OFST10 rw — S24, Offset at pixel 10
0x38 H3A_AFCOEF132 access per field — IIR filter coefficient data for SET 1.
  [27:16] COEFF3 rw — AF Engine IIR filter Coefficient #3 [Set 1] The range is signed -32 LTEQ value LTEQ 31 +63/64
  [11:0] COEFF2 rw — AF Engine IIR filter Coefficient #2 [Set 1] The range is signed -32 LTEQ value LTEQ 31 +63/64
0x38 exception_logging_data3 ro — The Exception Logging Data 3 Register contains the fourth word of the data.
  [9:0] bytecnt — Byte count.
0x38 ecc_aggr_cfg_fw_region_1_end_address_l access per field — The FW Region 1 End Address Low Register defines the end address bits 31 to 0 to include for the slave ksdw_ecc_aggr.cfg region 1 firewall.
  fields as ecc_aggr_cfg_fw_region_0_end_address_l
0x38 exception_logging_data3 ro — The Exception Logging Data 3 Register contains the fourth word of the data.
  [9:0] bytecnt — Byte count.
0x38 viss0_mst_isc_region_1_end_address_l access per field — The ISC Region 1 End Address Low Register defines the end included address bits 31 to 0 for the master .viss0_mst region 1 ISC.
  fields as viss0_mst_isc_region_0_end_address_l
0x3C sec_eoi_reg — EOI Register
  [0] eoi_wr
0x3C SETEVTENBL4 — System event detection enable register 4 (if number of events > 96)
  [n-97] Event{n}DetEn (n=97..128) — Event({n}) Detection Enable
0x3C sec_eoi_reg — EOI Register
  [0] eoi_wr
0x3C MESH_BASE_L — Lower 32-bit of Mesh Table Base Address
  [31:0] ADDR — Lower 32-bit of Read Base address for mesh offset table. Must be 16-byte aligned so four LSB are coded to 0
0x3C sec_eoi_reg — EOI Register
  [0] eoi_wr
0x3C RGBYUV_W02 access per field — Weight/Offset for Row0
  [28:16] Offset_0 rw — Offset_0 : (S13b)
  [11:0] W_03 rw — Weight W_03 : (S12 b)
0x3C PWL1_OFF4 access per field — Long frame Offset 4
  [23:0] OFST11 rw — S24, Offset at pixel 11
0x3C H3A_AFCOEF154 access per field — IIR filter coefficient data for SET 1.
  [27:16] COEFF5 rw — AF Engine IIR filter Coefficient #5 [Set 1] The range is signed -32 LTEQ value LTEQ 31 +63/64
  [11:0] COEFF4 rw — AF Engine IIR filter Coefficient #4 [Set 1] The range is signed -32 LTEQ value LTEQ 31 +63/64
0x3C ecc_aggr_cfg_fw_region_1_end_address_h — The FW Region 1 End Address High Register defines the end address bits 47 to 32 to include for the slave ksdw_ecc_aggr.cfg region 1 firewall.
  fields as ecc_aggr_cfg_fw_region_0_end_address_h
0x3C viss0_mst_isc_region_1_end_address_h — The ISC Region 1 End Address High Register defines the end address bits 47 to 32 for the master .viss0_mst region 1 ISC.
  [15:0] end_address_h — End address bits 47 to 32.
0x40 sec_status_reg0 — Interrupt Status Register 0
  [13] utc1_dru_state_buffer0_ecc_pend — Interrupt Pending Status for utc1_dru_state_buffer0_ecc_pend
  [12] utc1_dru_queue_buffer2_ecc_pend — Interrupt Pending Status for utc1_dru_queue_buffer2_ecc_pend
  [11] utc1_dru_queue_buffer1_ecc_pend — Interrupt Pending Status for utc1_dru_queue_buffer1_ecc_pend
  [10] utc1_dru_queue_buffer0_ecc_pend — Interrupt Pending Status for utc1_dru_queue_buffer0_ecc_pend
  [9] utc1_tpram_dru_response_buffer0_ecc_pend — Interrupt Pending Status for utc1_tpram_dru_response_buffer0_ecc_pend
  [8] utc1_dru_psi_edc_pend — Interrupt Pending Status for utc1_dru_psi_edc_pend
  [7] utc1_dru_eng_edc_pend — Interrupt Pending Status for utc1_dru_eng_edc_pend
  [6] utc0_dru_state_buffer0_ecc_pend — Interrupt Pending Status for utc0_dru_state_buffer0_ecc_pend
  [5] utc0_dru_queue_buffer2_ecc_pend — Interrupt Pending Status for utc0_dru_queue_buffer2_ecc_pend
  [4] utc0_dru_queue_buffer1_ecc_pend — Interrupt Pending Status for utc0_dru_queue_buffer1_ecc_pend
  [3] utc0_dru_queue_buffer0_ecc_pend — Interrupt Pending Status for utc0_dru_queue_buffer0_ecc_pend
  [2] utc0_tpram_dru_response_buffer0_ecc_pend — Interrupt Pending Status for utc0_tpram_dru_response_buffer0_ecc_pend
  [1] utc0_dru_psi_edc_pend — Interrupt Pending Status for utc0_dru_psi_edc_pend
  [0] utc0_dru_eng_edc_pend — Interrupt Pending Status for utc0_dru_eng_edc_pend
0x40 SETEVTENBL5 — System event detection enable register 5 (if number of events > 128)
  [n-129] Event{n}DetEn (n=147..160) — Event({n}) Detection Enable
  [17] Event1468DetEn — Event(146) Detection Enable
  [n-129] Event{n}DetEn (n=129..145) — Event({n}) Detection Enable
0x40 sec_status_reg0 — Interrupt Status Register 0
  [n+8] meshmem_b{n}_p1_ramecc_pend (n=0..3) — Interrupt Pending Status for meshmem_b{n}_p1_ramecc_pend
  [n+4] meshmem_b{n}_p0_ramecc_pend (n=0..3) — Interrupt Pending Status for meshmem_b{n}_p0_ramecc_pend
  [3] dualc_lut_b1_ramecc_pend — Interrupt Pending Status for dualc_lut_b1_ramecc_pend
  [2] dualc_lut_b0_ramecc_pend — Interrupt Pending Status for dualc_lut_b0_ramecc_pend
  [1] dualy_lut_b1_ramecc_pend — Interrupt Pending Status for dualy_lut_b1_ramecc_pend
  [0] dualy_lut_b0_ramecc_pend — Interrupt Pending Status for dualy_lut_b0_ramecc_pend
0x40 MESH_OFST — Defines the stride between rows for the Mesh table in bytes.
  [15:0] OFST — LDC Mesh table line offset, must be 16-byte aligned so four LSB are coded to 0
0x40 sec_status_reg0 — Interrupt Status Register 0
  [31] fcc_lut1_ram1_ramecc_pend — Interrupt Pending Status for fcc_lut1_ram1_ramecc_pend
  [30] fcc_lut1_ram0_ramecc_pend — Interrupt Pending Status for fcc_lut1_ram0_ramecc_pend
  [29] fcc_lut0_ram1_ramecc_pend — Interrupt Pending Status for fcc_lut0_ram1_ramecc_pend
  [28] fcc_lut0_ram0_ramecc_pend — Interrupt Pending Status for fcc_lut0_ram0_ramecc_pend
  [27] fcc_cont_lut3_ram1_ramecc_pend — Interrupt Pending Status for fcc_cont_lut3_ram1_ramecc_pend
  [26] fcc_cont_lut3_ram0_ramecc_pend — Interrupt Pending Status for fcc_cont_lut3_ram0_ramecc_pend
  [25] fcc_cont_lut2_ram1_ramecc_pend — Interrupt Pending Status for fcc_cont_lut2_ram1_ramecc_pend
  [24] fcc_cont_lut2_ram0_ramecc_pend — Interrupt Pending Status for fcc_cont_lut2_ram0_ramecc_pend
  [23] fcc_cont_lut1_ram1_ramecc_pend — Interrupt Pending Status for fcc_cont_lut1_ram1_ramecc_pend
  [22] fcc_cont_lut1_ram0_ramecc_pend — Interrupt Pending Status for fcc_cont_lut1_ram0_ramecc_pend
  [21] fcc_hist_ram1_ramecc_pend — Interrupt Pending Status for fcc_hist_ram1_ramecc_pend
  [20] fcc_hist_ram0_ramecc_pend — Interrupt Pending Status for fcc_hist_ram0_ramecc_pend
  [n+12] stat_mem{n}_ramecc_pend (n=0..7) — Interrupt Pending Status for stat_mem{n}_ramecc_pend
  [11] h3a_lut_ram1_ramecc_pend — Interrupt Pending Status for h3a_lut_ram1_ramecc_pend
  [10] h3a_lut_ram0_ramecc_pend — Interrupt Pending Status for h3a_lut_ram0_ramecc_pend
  [9] lsc_ramecc_pend — Interrupt Pending Status for lsc_ramecc_pend
  [8] dpc_lut_ramecc_pend — Interrupt Pending Status for dpc_lut_ramecc_pend
  [7] wdr_lut_ram1_ramecc_pend — Interrupt Pending Status for wdr_lut_ram1_ramecc_pend
  [6] wdr_lut_ram0_ramecc_pend — Interrupt Pending Status for wdr_lut_ram0_ramecc_pend
  [5] lut1_ram1_ramecc_pend — Interrupt Pending Status for lut1_ram1_ramecc_pend
  [4] lut1_ram0_ramecc_pend — Interrupt Pending Status for lut1_ram0_ramecc_pend
  [3] lut2_ram1_ramecc_pend — Interrupt Pending Status for lut2_ram1_ramecc_pend
  [2] lut2_ram0_ramecc_pend — Interrupt Pending Status for lut2_ram0_ramecc_pend
  [1] lut3_ram1_ramecc_pend — Interrupt Pending Status for lut3_ram1_ramecc_pend
  [0] lut3_ram0_ramecc_pend — Interrupt Pending Status for lut3_ram0_ramecc_pend
0x40 RGBYUV_W11 access per field — Weight/Offset for Row1
  [27:16] W_12 rw — Weight W_12 : (S12 b)
  [11:0] W_11 rw — Weight W_11 : (S12 b)
0x40 PWL1_WB_gain12 access per field — Long Frame white balance gain 1 and 2
  [28:16] WB_GAIN01 rw — U13Q9, WB gain at pixel 01
  [12:0] WB_GAIN00 rw — U13Q9, WB gain at pixel 00
0x40 H3A_AFCOEF176 access per field — IIR filter coefficient data for SET 1.
  [27:16] COEFF7 rw — AF Engine IIR filter Coefficient #7 [Set 1] The range is signed -32 LTEQ value LTEQ 31 +63/64
  [11:0] COEFF6 rw — AF Engine IIR filter Coefficient #6 [Set 1] The range is signed -32 LTEQ value LTEQ 31 +63/64
0x40 YEE_E_THR — The
  [9:0] yee_e_thr — The yee_e_thr is the Shrink Threshold before the LUT, scaled by 16x.
0x40 dru_comp_evt_set0 wo — DRU Completion Event Set Register
  [n] comp_evt{n} (n=0..31) — Set the Completion Event for channel {n}
0x40 status ro — Status Register for Queue 0
  [35:27] rd_total — This is the channel that the read half is currently working on.
  [26:18] rd_top — This is the channel that the read half is currently working on.
  [17:9] wr_total — This is the channel that the read half is currently working on.
  [8:0] wr_top — This is the channel that the write half is currently working on.
0x40 dru_comp_evt_set0 wo — DRU Completion Event Set Register
  [n] comp_evt{n} (n=0..63) — Set the Completion Event for channel {n}
0x40 status ro — Status Register for Queue 0
  fields as status
0x40 exception_pend_set — The Exception Logging Pending Set Register allows to set the pend signal.
  [0] pend_set — Write a 1 to set the exception pend signal.
0x40 exception_pend_set — The Exception Logging Pending Set Register allows to set the pend signal.
  [0] pend_set — Write a 1 to set the exception pend signal.
0x40 viss0_mst_isc_region_def_control access per field — The ISC Default Region Control Register defines the control fields for the master .viss0_mst region 2 ISC.
  [27:26] nopriv rw — Clear output priv attribute. If each bit is set then the outgoing priv bit is cleared.
  [25:24] priv rw — Set outgoing priv attribute. If each bit is set then the outgoing priv bit is set.
  [21] pass rw — No privID replacement, pass through value.
  [20] nonsec rw — Make outgoing non-secure.
  [19:16] sec rw — Make outgoing secure. A value of 0xA enables, others disable.
  [15:8] priv_id rw
  [6] def ro — Default region indication. The default region is used when all other regions do not match.
  [5] ch_mode ro — Enable channel mode to match region to a chanid value. Otherwise use address mode to match region to an address range.
  [4] lock rw — Lock region. Once set, the region values cannot be modified.
  [3:0] enable ro — Enable region. A value of 0xA enables, others disable.
0x44 SETEVTENBL6 — System event detection enable register 6 (if number of events > 160)
  [n-161] Event{n}DetEn (n=161..192) — Event({n}) Detection Enable
0x44 RD_BASE_H — Higher 16-bit of Input Frame Base Address
  [15:0] ADDR
0x44 sec_status_reg1 — Interrupt Status Register 1
  [5] eelut_1_ramecc_pend — Interrupt Pending Status for eelut_1_ramecc_pend
  [4] eelut_0_ramecc_pend — Interrupt Pending Status for eelut_0_ramecc_pend
  [3] lut_1_ramecc_pend — Interrupt Pending Status for lut_1_ramecc_pend
  [2] lut_0_ramecc_pend — Interrupt Pending Status for lut_0_ramecc_pend
  [1] fcc_lut2_ram1_ramecc_pend — Interrupt Pending Status for fcc_lut2_ram1_ramecc_pend
  [0] fcc_lut2_ram0_ramecc_pend — Interrupt Pending Status for fcc_lut2_ram0_ramecc_pend
0x44 RGBYUV_W12 access per field — Weight/Offset for Row1
  [28:16] Offset_1 rw — Offset_1 : (S13b)
  [11:0] W_13 rw — Weight W_13 : (S12 b)
0x44 PWL1_WB_gain34 access per field — Long Frame white balance gain 3 and 4
  [28:16] WB_GAIN11 rw — U13Q9, WB gain at pixel 11
  [12:0] WB_GAIN10 rw — U13Q9, WB gain at pixel 10
0x44 H3A_AFCOEF198 access per field — IIR filter coefficient data for SET 1.
  [27:16] COEFF9 rw — AF Engine IIR filter Coefficient #9 [Set 1] The range is signed -32 LTEQ value LTEQ 31 +63/64
  [11:0] COEFF8 rw — AF Engine IIR filter Coefficient #8 [Set 1] The range is signed -32 LTEQ value LTEQ 31 +63/64
